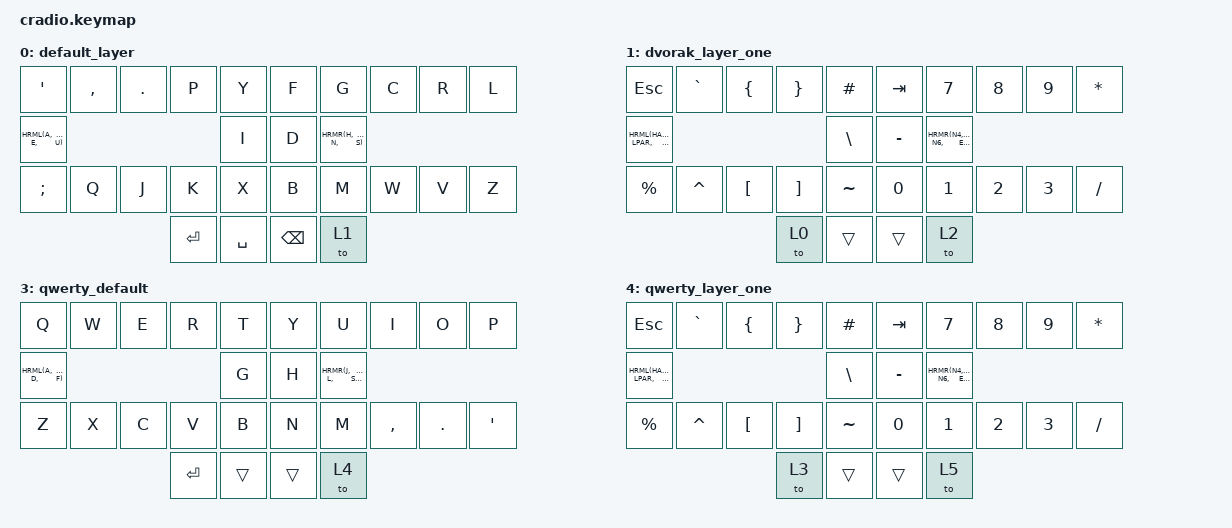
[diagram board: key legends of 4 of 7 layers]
// Copyright (c) 2022 The ZMK Contributors
// SPDX-License-Identifier: MIT

// TODO?
// - Function keys
// - Duplicate key reduction
// - Gaming layer?

#include <behaviors.dtsi>
#include <dt-bindings/zmk/keys.h>
#include <dt-bindings/zmk/bt.h>

// Home row mods macro
#define HRML(k1,k2,k3,k4) &hm LALT k1  &hm LMETA k2  &hm LCTRL k3  &hm LSHIFT k4
#define HRMR(k1,k2,k3,k4) &hm RSHIFT k1  &hm RCTRL k2  &hm RMETA k3  &hm RALT k4

/ {
    behaviors {
        hm: homerow_mods {
            compatible = "zmk,behavior-hold-tap";
            #binding-cells = <2>;
            tapping-term-ms = <150>;
            quick-tap-ms = <0>;
            flavor = "tap-preferred";
            bindings = <&kp>, <&kp>;
        };
    };

    combos {
        // Send me to the mgmt layer (bluetooth management)
        compatible = "zmk,combos";
        combo_settings {
            timeout-ms = <300>;
            key-positions = <30 31>;
            bindings = <&to 6>;
        };
    };

    keymap {
        compatible = "zmk,keymap";
        default_layer {
            bindings = <
        //╭──────────┬──────────┬──────────┬──────────┬──────────╮   ╭──────────┬──────────┬──────────┬──────────┬──────────╮
        //│ ' "      │ , <      │ . >      │ P        │ Y        │   │ F        │ G        │ C        │ R        │ L        │
           &kp SQT    &kp COMMA  &kp DOT    &kp P      &kp Y          &kp F      &kp G      &kp C      &kp R      &kp L
        //├──────────┼──────────┼──────────┼──────────┼──────────┤   ├──────────┼──────────┼──────────┼──────────┼──────────┤
        //│ A        │ O        │ E        │ U        │ I        │   │ D        │ H        │ T        │ N        │ S        │
           HRML(A,    O,         E,         U)         &kp I          &kp D      HRMR(H,    T,         N,         S)
        //├──────────┼──────────┼──────────┼──────────┼──────────┤   ├──────────┼──────────┼──────────┼──────────┼──────────┤
        //│ ; :      │ Q        │ J        │ K        │ X        │   │ B        │ M        │ W        │ V        │ Z        │
           &kp SEMI   &kp Q      &kp J      &kp K      &kp X          &kp B      &kp M      &kp W      &kp V      &kp Z
        //╰──────────┴──────────┴──────────┼──────────┼──────────┤   ├──────────┼──────────┼──────────┴──────────┴──────────╯
        //                                 │ ENTER    │ SPACE    │   │ BSPACE   │ SYM (D)  │  
                                            &kp ENTER  &kp SPACE      &kp BSPC   &to 1
        //                                 ╰──────────┴──────────╯   ╰──────────┴──────────╯
            >;
        };

        dvorak_layer_one {
            bindings = <
        //╭──────────┬──────────┬──────────┬──────────┬──────────╮   ╭──────────┬──────────┬──────────┬──────────┬──────────╮
        //│ <ESC>    │ ` ~      │ {        │ }        │ #        │   │ <TAB>    │ 7 &      │ 8 *      │ 9 (      │ *        │
           &kp ESC    &kp GRAVE  &kp LBRC   &kp RBRC   &kp HASH       &kp TAB    &kp N7     &kp N8     &kp N9     &kp ASTRK
        //├──────────┼──────────┼──────────┼──────────┼──────────┤   ├──────────┼──────────┼──────────┼──────────┼──────────┤
        //│ # ALT    │ $ META   │ ( CTRL   │ ) SHFT   │ \ |      │   │ - _      │ 4 $ SHFT │ 5 % CTRL │ 6 ^ META │ = ALT    │
           HRML(HASH, DLLR,      LPAR,      RPAR)      &kp BSLH       &kp MINUS  HRMR(N4,   N5,        N6,        EQUAL)
        //├──────────┼──────────┼──────────┼──────────┼──────────┤   ├──────────┼──────────┼──────────┼──────────┼──────────┤
        //│ %        │ ^        │ [ {      │ ] }      │ ~        │   │ 0 )      │ 1 !      │ 2 @      │ 3 #      │ /  ?     │
           &kp PRCNT  &kp CARET  &kp LBKT   &kp RBKT   &kp TILDE      &kp N0     &kp N1     &kp N2     &kp N3     &kp FSLH
        //╰──────────┴──────────┴──────────┼──────────┼──────────┤   ├──────────┼──────────┼──────────┴──────────┴──────────╯
        //                                 │ (DVORAK) │ SPACE    │   │ BSPACE   │ EXTRA (D)│  
                                            &to 0      &trans         &trans     &to 2
        //                                 ╰──────────┴──────────╯   ╰──────────┴──────────╯
            >;
        };

        dvorak_layer_two {
            bindings = <
        //╭──────────┬──────────┬──────────┬──────────┬──────────╮   ╭──────────┬──────────┬──────────┬──────────┬──────────╮
        //│          │          │          │          │          │   │          │          │          │          │          │
           &none      &none      &none      &none      &none          &none      &none      &none      &none      &kp DEL 
        //├──────────┼──────────┼──────────┼──────────┼──────────┤   ├──────────┼──────────┼──────────┼──────────┼──────────┤
        //│          │          │          │          │          │   │          │          │          │          │          │
           &none      &none      &none      &none      &none          &kp LEFT   &kp DOWN   &kp UP     &kp RIGHT  &none  
        //├──────────┼──────────┼──────────┼──────────┼──────────┤   ├──────────┼──────────┼──────────┼──────────┼──────────┤
        //│          │          │          │          │          │   │          │          │          │          │          │
           &none      &none      &none      &none      &none          &none      &none      &none      &none      &none
        //╰──────────┴──────────┴──────────┼──────────┼──────────┤   ├──────────┼──────────┼──────────┴──────────┴──────────╯
        //                                 │ (DVORAK) │ SPACE    │   │ BSPACE   │ SYM (D)  │  
                                            &to 0      &trans         &trans     &to 1
        //                                 ╰──────────┴──────────╯   ╰──────────┴──────────╯
            >;
        };

        qwerty_default {
            bindings = <
        //╭──────────┬──────────┬──────────┬──────────┬──────────╮   ╭──────────┬──────────┬──────────┬──────────┬──────────╮
        //│  Q       │  W       │  E       │  R       │  T       │   │  Y       │  U       │  I       │  O       │  P       │
           &kp Q      &kp W      &kp E      &kp R      &kp T          &kp Y      &kp U      &kp I      &kp O      &kp P
        //├──────────┼──────────┼──────────┼──────────┼──────────┤   ├──────────┼──────────┼──────────┼──────────┼──────────┤
        //│  A       │  S       │  D       │  F       │  G       │   │  H       │  J       │  K       │  L       │ : ;      │
           HRML(A,    S,         D,         F)         &kp G          &kp H      HRMR(J,    K,         L,         SEMI)
        //├──────────┼──────────┼──────────┼──────────┼──────────┤   ├──────────┼──────────┼──────────┼──────────┼──────────┤
        //│  Z       │  X       │  C       │  V       │  B       │   │  N       │  M       │ ,        │ .        │ ' "      │
           &kp Z      &kp X      &kp C      &kp V      &kp B          &kp N      &kp M      &kp COMMA  &kp DOT    &kp SQT
        //╰──────────┴──────────┴──────────┼──────────┼──────────┤   ├──────────┼──────────┼──────────┴──────────┴──────────╯
        //                                 │ ENTER    │ SPACE    │   │ BSPACE   │ SYM (Q)  │  
                                            &kp ENTER  &trans         &trans     &to 4
        //                                 ╰──────────┴──────────╯   ╰──────────┴──────────╯
            >;
        };

        qwerty_layer_one {
            bindings = <
        //╭──────────┬──────────┬──────────┬──────────┬──────────╮   ╭──────────┬──────────┬──────────┬──────────┬──────────╮
        //│ <ESC>    │  `       │ {        │ }        │ #        │   │ <TAB>    │ 7 &      │ 8 *      │ 9 (      │ *        │
           &kp ESC    &kp GRAVE  &kp LBRC   &kp RBRC   &kp HASH       &kp TAB    &kp N7     &kp N8     &kp N9     &kp ASTRK
        //├──────────┼──────────┼──────────┼──────────┼──────────┤   ├──────────┼──────────┼──────────┼──────────┼──────────┤
        //│ # ALT    │ $ META   │ ( CTRL   │ ) SHFT   │ \ |      │   │ - _      │ 4 $ SHFT │ 5 % CTRL │ 6 ^ META │ = + ALT  │
           HRML(HASH, DLLR,       LPAR,      RPAR)   &kp BSLH       &kp MINUS   HRMR(N4,     N5,         N6,     EQUAL)
        //├──────────┼──────────┼──────────┼──────────┼──────────┤   ├──────────┼──────────┼──────────┼──────────┼──────────┤
        //│ %        │ ^        │ [ }      │ ] }      │ ~        │   │ 0 )      │ 1 !      │ 2 @      │ 3 #      │ / ?      │
           &kp PRCNT  &kp CARET  &kp LBKT   &kp RBKT   &kp TILDE      &kp N0     &kp N1     &kp N2     &kp N3     &kp FSLH
        //╰──────────┴──────────┴──────────┼──────────┼──────────┤   ├──────────┼──────────┼──────────┴──────────┴──────────╯
        //                                 │ (QWERTY) │ SPACE    │   │ BSPACE   │ EXTRA (Q)│  
                                             &to 3      &trans         &trans     &to 5
        //                                 ╰──────────┴──────────╯   ╰──────────┴──────────╯
            >;
        };

        qwerty_layer_two {
            bindings = <
        //╭──────────┬──────────┬──────────┬──────────┬──────────╮   ╭──────────┬──────────┬──────────┬──────────┬──────────╮
        //│          │          │          │          │          │   │          │          │          │          │          │
           &none      &none      &none      &none      &none          &none      &none      &none      &none      &kp DEL 
        //├──────────┼──────────┼──────────┼──────────┼──────────┤   ├──────────┼──────────┼──────────┼──────────┼──────────┤
        //│          │          │          │          │          │   │          │          │          │          │          │
           &none      &none      &none      &none      &none          &kp LEFT   &kp DOWN   &kp UP     &kp RIGHT  &none  
        //├──────────┼──────────┼──────────┼──────────┼──────────┤   ├──────────┼──────────┼──────────┼──────────┼──────────┤
        //│          │          │          │          │          │   │          │          │          │          │          │
           &none      &none      &none      &none      &none          &none      &none      &none      &none      &none 
        //╰──────────┴──────────┴──────────┼──────────┼──────────┤   ├──────────┼──────────┼──────────┴──────────┴──────────╯
        //                                 │ (QWERTY) │ SPACE    │   │ BSPACE   │ SYM (Q)  │  
                                            &to 3      &trans         &trans     &to 4
        //                                 ╰──────────┴──────────╯   ╰──────────┴──────────╯
            >;
        };

        mgmt_layer {
            bindings = <
        //╭────────────┬────────────┬────────────┬────────────┬────────────╮   ╭────────────┬────────────┬────────────┬────────────┬────────────╮
        //│ CLR BT     │            │            │            │ (DVORAK)   │   │ (QWERTY)   │            │            │            │            │
           &bt BT_CLR   &none        &none        &none        &to 0            &to 3        &none        &none        &none        &none 
        //├────────────┼────────────┼────────────┼────────────┼────────────┤   ├────────────┼────────────┼────────────┼────────────┼────────────┤
        //│            │            │            │            │            │   │            │            │            │            │            │
           &none      &none      &none      &none      &none                    &none        &none        &none        &none        &none  
        //├────────────┼────────────┼────────────┼────────────┼────────────┤   ├────────────┼────────────┼────────────┼────────────┼────────────┤
        //│ DEVICE 1   │ DEVICE 2   │ DEVICE 3   │ DEVICE 4   │ DEVICE 5   │   │            │            │            │            │            │
           &bt BT_SEL 0 &bt BT_SEL 1 &bt BT_SEL 2 &bt BT_SEL 3 &bt BT_SEL 4     &none        &none        &none        &none        &none
        //╰────────────┴────────────┴────────────┼────────────┼────────────┤   ├────────────┼────────────┼────────────┴────────────┴────────────╯
        //                                       │            │            │   │            │            │  
                                                  &none        &none            &none        &none
        //                                       ╰────────────┴────────────╯   ╰────────────┴────────────╯
            >;
        };
    };
};
